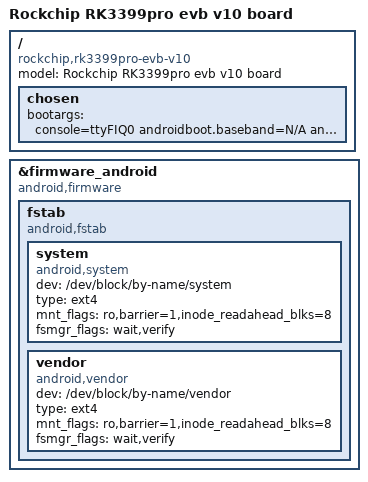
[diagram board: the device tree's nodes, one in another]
// SPDX-License-Identifier: (GPL-2.0+ OR MIT)
/*
 * Copyright (c) 2018 Fuzhou Rockchip Electronics Co., Ltd
 *
 */

/dts-v1/;
#include "rk3399pro-evb-v10.dtsi"

/ {
	model = "Rockchip RK3399pro evb v10 board";
	compatible = "rockchip,rk3399pro-evb-v10", "rockchip,rk3399pro";

	chosen {
		bootargs = "console=ttyFIQ0 androidboot.baseband=N/A androidboot.selinux=permissive androidboot.veritymode=enforcing androidboot.hardware=rk30board androidboot.console=ttyFIQ0 init=/init earlycon=uart8250,mmio32,0xff1a0000 swiotlb=1 coherent_pool=1m";
	};
};

&firmware_android {
	compatible = "android,firmware";
	fstab {
		compatible = "android,fstab";
		system {
			compatible = "android,system";
			dev = "/dev/block/by-name/system";
			type = "ext4";
			mnt_flags = "ro,barrier=1,inode_readahead_blks=8";
			fsmgr_flags = "wait,verify";
		};
		vendor {
			compatible = "android,vendor";
			dev = "/dev/block/by-name/vendor";
			type = "ext4";
			mnt_flags = "ro,barrier=1,inode_readahead_blks=8";
			fsmgr_flags = "wait,verify";
		};
	};
};
